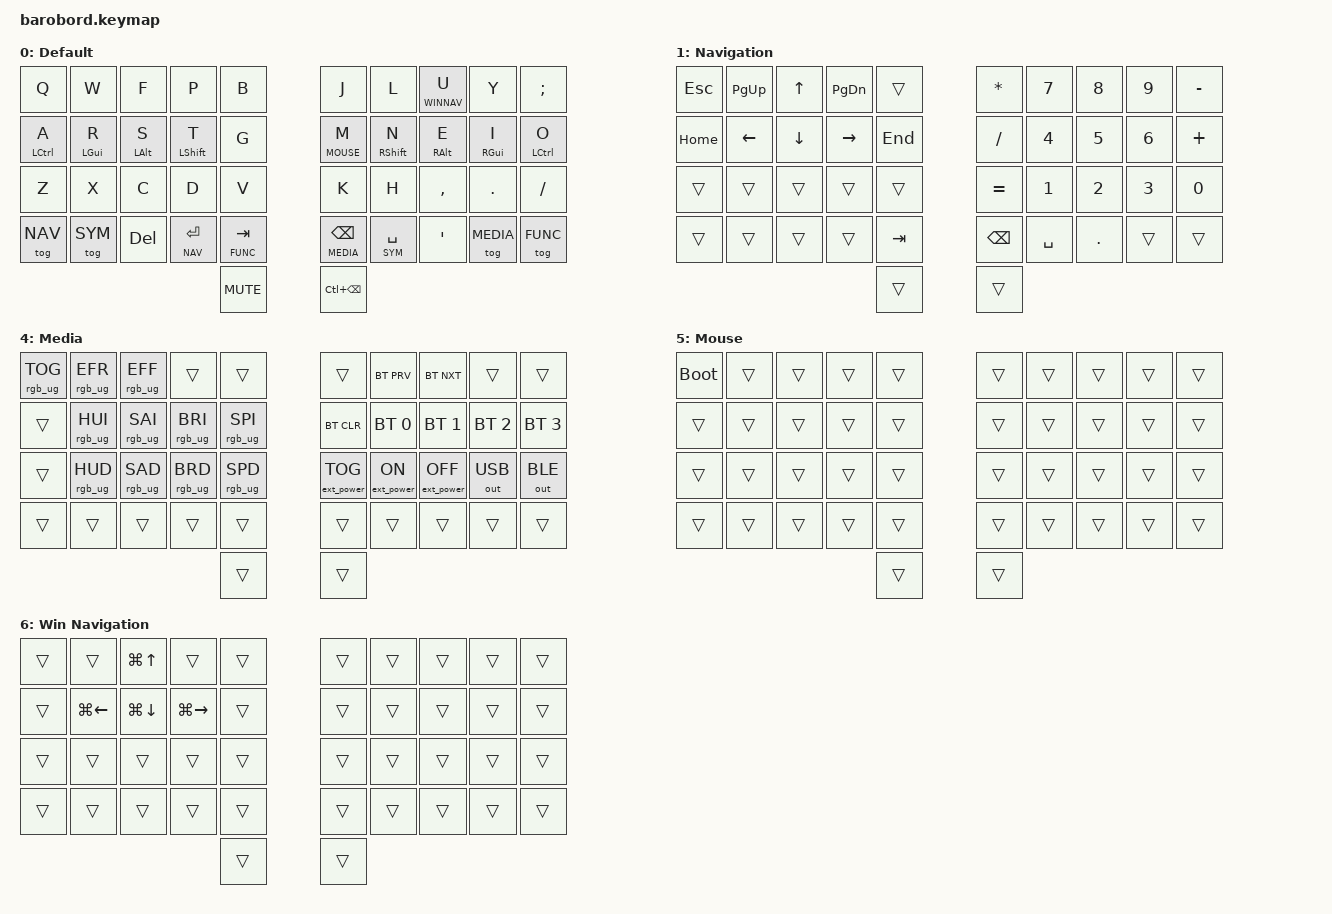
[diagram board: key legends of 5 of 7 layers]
#include <behaviors.dtsi>
#include <dt-bindings/zmk/keys.h>
#include <dt-bindings/zmk/rgb.h>
#include <dt-bindings/zmk/bt.h>
#include <dt-bindings/zmk/ext_power.h>
#include <dt-bindings/zmk/outputs.h>

#define DEFAULT 0
#define NAV     1
#define SYM     2
#define FUNC    3
#define MEDIA   4
#define MOUSE   5
#define WINNAV  6

&caps_word {
    continue-list = <UNDERSCORE MINUS>;
};

/ {
    combos {
        compatible = "zmk,combos";
        combo_undo {
            timeout-ms = <50>;
            key-positions = <26 27>;
            bindings = <&kp LC(Z)>;
        };
        combo_q {
            timeout-ms = <50>;
            key-positions = <27 28>;
            bindings = <&kp Q>;
        };
        combo_semicolon {
            timeout-ms = <50>;
            key-positions = <33 34>;
            bindings = <&kp SEMI>;
        };
    };
};

/ {

    sensors {
        compatible = "zmk,keymap-sensors";
        sensors = <&encoder_1 &encoder_2>;
    };

    behaviors {
        hm: homerow_mods {
            compatible = "zmk,behavior-hold-tap";
            label = "HOMEROW_MODS";
            #binding-cells = <2>;
            tapping-term-ms = <200>;
            quick_tap_ms = <0>;
            flavor = "balanced";
            bindings = <&kp>, <&kp>;
        };
        hs: homerow_shift {
            compatible = "zmk,behavior-hold-tap";
            label = "HOMEROW_SHIFT";
            #binding-cells = <2>;
            tapping-term-ms = <175>;
            quick_tap_ms = <0>;
            flavor = "balanced";
            bindings = <&kp>, <&kp>;
        };
    };

    keymap {
        compatible = "zmk,keymap";

        default_layer {
            label = "Default";

            sensor-bindings = <&inc_dec_kp C_VOLUME_DOWN C_VOLUME_UP &inc_dec_kp C_VOLUME_DOWN C_VOLUME_UP>;

            bindings = <
               &kp Q        &kp W        &kp F       &kp P         &kp B                                       &kp J         &kp L        &lt WINNAV U  &kp Y       &kp SEMI
               &hm LCTL A   &hm LGUI R   &hm LALT S  &hs LSHIFT T  &kp G                                       &lt MOUSE M   &hs RSHIFT N &hm RALT E    &hm RGUI I  &hm LCTL O
               &kp Z        &kp X        &kp C       &kp D         &kp V                                       &kp K         &kp H        &kp COMMA     &kp DOT     &kp FSLH
                            &tog NAV     &tog SYM    &kp DEL       &lt NAV RET  &lt FUNC TAB  &lt MEDIA BSPC   &lt SYM SPACE &kp SQT      &tog MEDIA    &tog FUNC
                                                                                &kp C_MUTE    &kp LC(BSPC)
            >;
        };

        nav_layer {
            label = "Navigation";
            
            sensor-bindings = <&inc_dec_kp C_VOLUME_DOWN C_VOLUME_UP &inc_dec_kp C_VOLUME_DOWN C_VOLUME_UP>;
            
            bindings = <
               &kp ESC      &kp PG_UP    &kp UP      &kp PG_DN     &trans                                      &kp ASTRK     &kp N7       &kp N8        &kp N9      &kp MINUS
               &kp HOME     &kp LEFT     &kp DOWN    &kp RIGHT     &kp END                                     &kp FSLH      &kp N4       &kp N5        &kp N6      &kp PLUS
               &trans       &trans       &trans      &trans        &trans                                      &kp EQUAL     &kp N1       &kp N2        &kp N3      &kp N0
                            &trans       &trans      &trans        &trans       &kp TAB       &kp BSPC         &kp SPACE     &kp DOT      &trans        &trans
                                                                                &trans        &trans
            >;
        };

        sym_layer {
            label = "Symbols";
            
            sensor-bindings = <&inc_dec_kp C_VOLUME_DOWN C_VOLUME_UP &inc_dec_kp C_VOLUME_DOWN C_VOLUME_UP>;
            
            bindings = <
               &kp EXCL     &kp AT       &kp HASH        &kp DLLR         &kp PRCNT                                   &kp CARET     &kp AMPS          &kp ASTRK     &kp UNDER   &kp EQUAL
               &kp MINUS    &kp LBKT     &kp LBRC        &kp LPAR         &kp LT                                      &kp GT        &kp RPAR          &kp RBRC      &kp RBKT    &kp PLUS
               &kp CAPS     &kp GRAVE    &kp LC(LS(TAB)) &kp LC(LG(LEFT)) &caps_word                                  &trans        &kp LC(LG(RIGHT)) &kp LC(TAB)   &trans      &kp BSLH
                            &trans       &trans          &trans           &kp RET       &kp DEL        &kp BSPC       &trans        &trans            &trans
                                                                                &trans        &trans
            >;
        };

        func_layer {
            label = "Function";

            sensor-bindings = <&inc_dec_kp C_VOLUME_DOWN C_VOLUME_UP &inc_dec_kp C_VOLUME_DOWN C_VOLUME_UP>;
            
            bindings = <
               &trans       &kp LS(PG_UP) &kp LS(UP)   &kp LS(PG_DN) &trans                                      &kp C_PLAY_PAUSE &kp F7       &kp F8        &kp F9      &kp F10
               &kp LS(HOME) &kp LS(LEFT)  &kp LS(DOWN) &kp LS(RIGHT) &kp LS(END)                                 &kp K_VOL_UP     &kp F4       &kp F5        &kp F6      &kp F11
               &trans       &trans        &trans       &trans        &kp C_MUTE                                  &kp K_VOL_DN     &kp F1       &kp F2        &kp F3      &kp F12
                            &trans        &trans       &trans        &trans        &trans         &trans         &trans           &kp SPACE    &trans
                                                                                   &trans         &trans
            >;
        };

        media_layer {
            label = "Media";
            
            sensor-bindings = <&inc_dec_kp C_VOLUME_DOWN C_VOLUME_UP &inc_dec_kp C_VOLUME_DOWN C_VOLUME_UP>;
            
            bindings = <
               &rgb_ug RGB_TOG  &rgb_ug RGB_EFR  &rgb_ug RGB_EFF &trans            &trans                            &trans             &bt BT_PRV        &bt BT_NXT         &trans         &trans
               &trans           &rgb_ug RGB_HUI  &rgb_ug RGB_SAI &rgb_ug RGB_BRI   &rgb_ug RGB_SPI                   &bt BT_CLR         &bt BT_SEL 0      &bt BT_SEL 1       &bt BT_SEL 2   &bt BT_SEL 3
               &trans           &rgb_ug RGB_HUD  &rgb_ug RGB_SAD &rgb_ug RGB_BRD   &rgb_ug RGB_SPD                   &ext_power EP_TOG  &ext_power EP_ON  &ext_power EP_OFF  &out OUT_USB   &out OUT_BLE
                                &trans           &trans          &trans            &trans        &trans    &trans    &trans             &trans            &trans             &trans
                                                                                                 &trans    &trans
            >;
        };

        mouse_layer {
            label = "Mouse";
            
            sensor-bindings = <&inc_dec_kp C_VOLUME_DOWN C_VOLUME_UP &inc_dec_kp C_VOLUME_DOWN C_VOLUME_UP>;
            
            bindings = <
               &bootloader &trans      &trans      &trans      &trans                                           &trans      &trans      &trans      &trans      &trans
               &trans      &trans      &trans      &trans      &trans                                           &trans      &trans      &trans      &trans      &trans
               &trans      &trans      &trans      &trans      &trans                                           &trans      &trans      &trans      &trans      &trans
                           &trans      &trans      &trans      &trans          &trans         &trans            &trans      &trans      &trans      &trans
                                                                               &trans         &trans
            >;
        };

        winnav_layer {
            label = "Win Navigation";
            
            sensor-bindings = <&inc_dec_kp C_VOLUME_DOWN C_VOLUME_UP &inc_dec_kp C_VOLUME_DOWN C_VOLUME_UP>;
            
            bindings = <
               &trans       &trans       &kp LG(UP)   &trans        &trans                                      &trans      &trans      &trans      &trans      &trans
               &trans       &kp LG(LEFT) &kp LG(DOWN) &kp LG(RIGHT) &trans                                      &trans      &trans      &trans      &trans      &trans
               &trans       &trans       &trans       &trans        &trans                                      &trans      &trans      &trans      &trans      &trans
                            &trans       &trans       &trans        &trans        &trans         &trans         &trans      &trans      &trans      &trans
                                                                                  &trans         &trans
            >;
        };
    };
};
